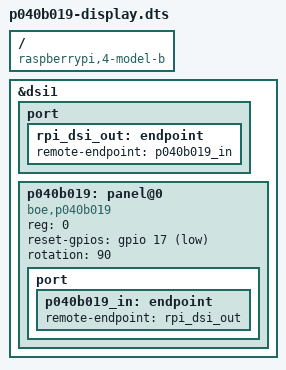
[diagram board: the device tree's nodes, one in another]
// SPDX-License-Identifier: GPL-2.0-only
/*
 * Device tree overlay for P040B019-MIPI-CTP display (ST7701P)
 *
 * Panel: P040B019, DSI1, 2-lane, 480×800
 * Backlight: DCS command-based (fallback when no pwm_bl driver)
 * Display RESET: GPIO17 (open-drain required!)
 *
 * Note: touch overlay (st7701p-touch) must be loaded separately
 */

/dts-v1/;
/plugin/;

/ {
	compatible = "raspberrypi,4-model-b", "brcm,bcm2711";

	fragment@0 {
		target = <&dsi1>;
		__overlay__ {
			status = "okay";
			#address-cells = <1>;
			#size-cells = <0>;

			port {
				rpi_dsi_out: endpoint {
					remote-endpoint = <&p040b019_in>;
				};
			};

			p040b019: panel@0 {
				compatible = "boe,p040b019";
				status = "okay";
				reg = <0>;
				reset-gpios = <&gpio 17 3>; /* GPIO_ACTIVE_LOW(1) | GPIO_OPEN_SOURCE(2) */
				rotation = <90>;

				port {
					p040b019_in: endpoint {
						remote-endpoint = <&rpi_dsi_out>;
					};
				};
			};
		};
	};
};
